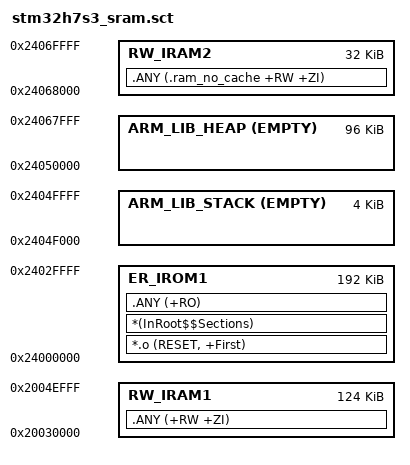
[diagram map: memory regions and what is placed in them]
;*******************************************************************
;* STM32H7S3 linker scatter file (running code from internal SRAM) *
;*******************************************************************

LR_IROM1 0x24000000 0x30000
{
   ER_IROM1 0x24000000 0x30000
   {
      *.o (RESET, +First)
      *(InRoot$$Sections)
      .ANY (+RO)
   }
   
   RW_IRAM1 0x20030000 0x1F000
   { 
      .ANY (+RW +ZI)
   }
   
   ARM_LIB_STACK 0x24050000 EMPTY -0x1000
   {
   }
   
   ARM_LIB_HEAP 0x24050000 EMPTY 0x18000
   {
   }
   
   RW_IRAM2 0x24068000 0x8000
   {
      .ANY (.ram_no_cache +RW +ZI)
   }
}
